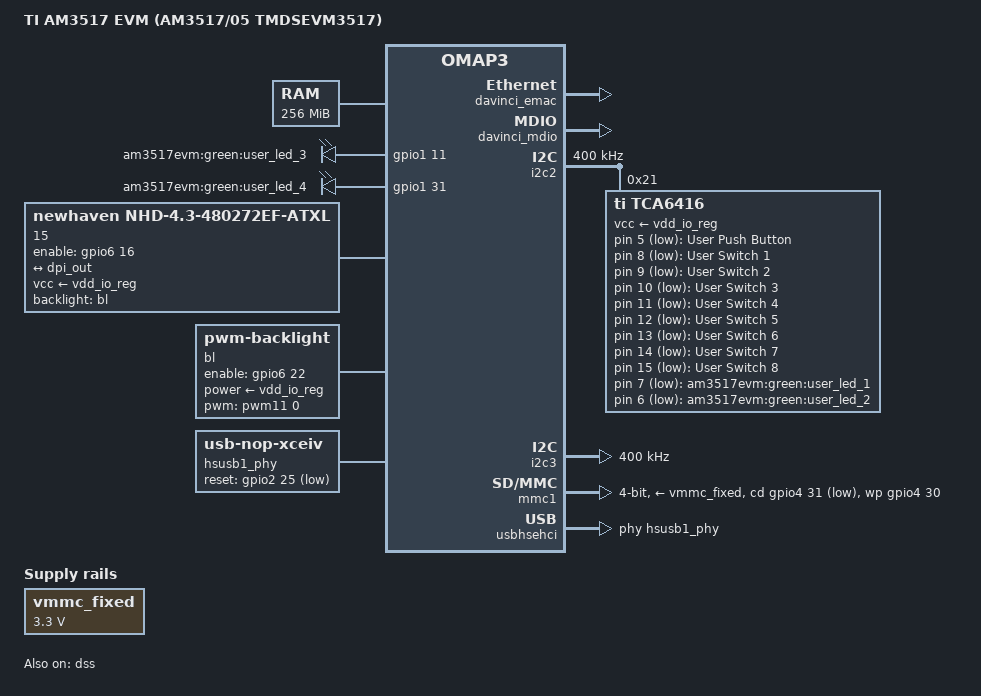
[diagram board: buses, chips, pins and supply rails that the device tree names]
/dts-v1/;
#include "am3517.dtsi"
#include "am3517-som.dtsi"
#include "am3517-evm-ui.dtsi"
#include <dt-bindings/input/input.h>
/ {
	model = "TI AM3517 EVM (AM3517/05 TMDSEVM3517)";
	compatible = "ti,am3517-evm", "ti,am3517", "ti,omap3";
	aliases {
		display0 = &lcd0;
	};
	chosen {
		stdout-path = &uart3;
	};
	memory@80000000 {
		device_type = "memory";
		reg = <0x80000000 0x10000000>;  
	};
	vmmc_fixed: vmmc {
		compatible = "regulator-fixed";
		regulator-name = "vmmc_fixed";
		regulator-min-microvolt = <3300000>;
		regulator-max-microvolt = <3300000>;
	};
	gpio-keys {
		compatible = "gpio-keys-polled";
		poll-interval = <100>;
		button-user {
			label = "User Push Button";
			linux,code = <BTN_0>;
			gpios = <&tca6416 5 GPIO_ACTIVE_LOW>;
		};
		switch-1 {
			label = "User Switch 1";
			linux,code = <BTN_1>;
			gpios = <&tca6416 8 GPIO_ACTIVE_LOW>;
		};
		switch-2 {
			label = "User Switch 2";
			linux,code = <BTN_2>;
			gpios = <&tca6416 9 GPIO_ACTIVE_LOW>;
		};
		switch-3 {
			label = "User Switch 3";
			linux,code = <BTN_3>;
			gpios = <&tca6416 10 GPIO_ACTIVE_LOW>;
		};
		switch-4 {
			label = "User Switch 4";
			linux,code = <BTN_4>;
			gpios = <&tca6416 11 GPIO_ACTIVE_LOW>;
		};
		switch-5 {
			label = "User Switch 5";
			linux,code = <BTN_5>;
			gpios = <&tca6416 12 GPIO_ACTIVE_LOW>;
		};
		switch-6 {
			label = "User Switch 6";
			linux,code = <BTN_6>;
			gpios = <&tca6416 13 GPIO_ACTIVE_LOW>;
		};
		switch-7 {
			label = "User Switch 7";
			linux,code = <BTN_7>;
			gpios = <&tca6416 14 GPIO_ACTIVE_LOW>;
		};
		switch-8 {
			label = "User Switch 8";
			linux,code = <BTN_8>;
			gpios = <&tca6416 15 GPIO_ACTIVE_LOW>;
		};
	};
	gpio-leds {
		compatible = "gpio-leds";
		pinctrl-names = "default";
		pinctrl-0 = <&leds_pins>;
		user_led_1 {
			label = "am3517evm:green:user_led_1";
			gpios = <&tca6416 7 GPIO_ACTIVE_LOW>;
			default-state = "on";
		};
		user_led_2 {
			label = "am3517evm:green:user_led_2";
			gpios = <&tca6416 6 GPIO_ACTIVE_LOW>;
			default-state = "on";
		};
		user_led_3 {
			label = "am3517evm:green:user_led_3";
			gpios = <&gpio1 11 GPIO_ACTIVE_HIGH>;
			linux,default-trigger = "mmc0";  
		};
		user_led_4 {
			label = "am3517evm:green:user_led_4";
			gpios = <&gpio1 31 GPIO_ACTIVE_HIGH>;
			linux,default-trigger = "heartbeat";
		};
	};
	lcd0: display@0 {
		compatible = "newhaven,nhd-4.3-480272ef-atxl";
		label = "15";
		backlight = <&bl>;
		enable-gpios = <&gpio6 16 GPIO_ACTIVE_HIGH>;	 
		vcc-supply = <&vdd_io_reg>;
		port {
			lcd_in: endpoint {
				remote-endpoint = <&dpi_out>;
			};
		};
	};
	bl: backlight {
		compatible = "pwm-backlight";
		pinctrl-names = "default";
		power-supply = <&vdd_io_reg>;
		pinctrl-0 = <&backlight_pins>;
		pwms = <&pwm11 0 5000000 0>;
		brightness-levels = <0 10 20 30 40 50 60 70 80 90 100>;
		default-brightness-level = <7>;
		enable-gpios = <&gpio6 22 GPIO_ACTIVE_HIGH>;  
	};
	pwm11: pwm-11 {
		compatible = "ti,omap-dmtimer-pwm";
		pinctrl-names = "default";
		pinctrl-0 = <&pwm_pins>;
		ti,timers = <&timer11>;
		#pwm-cells = <3>;
		ti,clock-source = <0x01>;
	};
	hsusb1_phy: hsusb1_phy {
		pinctrl-names = "default";
		pinctrl-0 = <&hsusb1_rst_pins>;
		compatible = "usb-nop-xceiv";
		reset-gpios = <&gpio2 25 GPIO_ACTIVE_LOW>;  
		#phy-cells = <0>;
	};
};
&davinci_emac {
	pinctrl-names = "default";
	pinctrl-0 = <&ethernet_pins>;
	status = "okay";
};
&davinci_mdio {
	status = "okay";
};
&dss {
	status = "okay";
	pinctrl-names = "default";
	pinctrl-0 = <&dss_dpi_pins>;
	vdds_dsi-supply = <&vdd_io_reg>;
	vdda_video-supply = <&vdd_io_reg>;
	port {
		dpi_out: endpoint {
			remote-endpoint = <&lcd_in>;
			data-lines = <16>;
		};
	};
};
&i2c2 {
	pinctrl-names = "default";
	pinctrl-0 = <&i2c2_pins>;
	clock-frequency = <400000>;
	tca6416: gpio@21 {
		compatible = "ti,tca6416";
		reg = <0x21>;
		gpio-controller;
		#gpio-cells = <2>;
		vcc-supply = <&vdd_io_reg>;
	};
};
&i2c3 {
	pinctrl-names = "default";
	pinctrl-0 = <&i2c3_pins>;
	clock-frequency = <400000>;
};
&mmc1 {
	status = "okay";
	pinctrl-names = "default";
	pinctrl-0 = <&mmc1_pins>;
	vmmc-supply = <&vmmc_fixed>;
	bus-width = <4>;
	wp-gpios = <&gpio4 30 GPIO_ACTIVE_HIGH>;  
	cd-gpios = <&gpio4 31 GPIO_ACTIVE_LOW>;  
};
&mmc3 {
	status = "disabled";
};
&usbhshost {
	pinctrl-names = "default";
	pinctrl-0 = <&hsusb1_pins>;
	port1-mode = "ehci-phy";
};
&usbhsehci {
	phys = <&hsusb1_phy>;
};
&omap3_pmx_core {
	ethernet_pins: ethernet-pins {
		pinctrl-single,pins = <
			OMAP3_CORE1_IOPAD(0x21fe, PIN_INPUT | MUX_MODE0)  
			OMAP3_CORE1_IOPAD(0x2200, MUX_MODE0)  
			OMAP3_CORE1_IOPAD(0x2202, PIN_INPUT_PULLDOWN | MUX_MODE0)  
			OMAP3_CORE1_IOPAD(0x2204, PIN_INPUT_PULLDOWN | MUX_MODE0)  
			OMAP3_CORE1_IOPAD(0x2206, PIN_INPUT_PULLDOWN | MUX_MODE0)  
			OMAP3_CORE1_IOPAD(0x2208, PIN_OUTPUT_PULLDOWN | MUX_MODE0)  
			OMAP3_CORE1_IOPAD(0x220a, PIN_OUTPUT_PULLDOWN | MUX_MODE0)  
			OMAP3_CORE1_IOPAD(0x220c, PIN_OUTPUT_PULLDOWN | MUX_MODE0)  
			OMAP3_CORE1_IOPAD(0x220e, PIN_OUTPUT_PULLDOWN |MUX_MODE0)  
			OMAP3_CORE1_IOPAD(0x2210, PIN_INPUT_PULLDOWN | MUX_MODE0)  
		>;
	};
	i2c2_pins: i2c2-pins {
		pinctrl-single,pins = <
			OMAP3_CORE1_IOPAD(0x21be, PIN_INPUT_PULLUP | MUX_MODE0)   
			OMAP3_CORE1_IOPAD(0x21c0, PIN_INPUT_PULLUP | MUX_MODE0)   
		>;
	};
	i2c3_pins: i2c3-pins {
		pinctrl-single,pins = <
			OMAP3_CORE1_IOPAD(0x21c2, PIN_INPUT_PULLUP | MUX_MODE0)   
			OMAP3_CORE1_IOPAD(0x21c4, PIN_INPUT_PULLUP | MUX_MODE0)   
		>;
	};
	mmc1_pins: mmc1-pins {
		pinctrl-single,pins = <
			OMAP3_CORE1_IOPAD(0x2144, PIN_INPUT_PULLUP | MUX_MODE0)	 
			OMAP3_CORE1_IOPAD(0x2146, PIN_INPUT_PULLUP | MUX_MODE0)	 
			OMAP3_CORE1_IOPAD(0x2148, PIN_INPUT_PULLUP | MUX_MODE0)	 
			OMAP3_CORE1_IOPAD(0x214a, PIN_INPUT_PULLUP | MUX_MODE0)	 
			OMAP3_CORE1_IOPAD(0x214c, PIN_INPUT_PULLUP | MUX_MODE0)	 
			OMAP3_CORE1_IOPAD(0x214e, PIN_INPUT_PULLUP | MUX_MODE0)	 
			OMAP3_CORE1_IOPAD(0x2150, PIN_INPUT_PULLUP | MUX_MODE4)  
			OMAP3_CORE1_IOPAD(0x2152, PIN_INPUT_PULLUP | MUX_MODE4)  
		>;
	};
	pwm_pins: pwm-pins {
		pinctrl-single,pins = <
			OMAP3_CORE1_IOPAD(0x21dc, PIN_OUTPUT | MUX_MODE1)        
		>;
	};
	backlight_pins: backlight-pins {
		pinctrl-single,pins = <
			OMAP3_CORE1_IOPAD(0x21de, PIN_OUTPUT | MUX_MODE4)        
		>;
	};
	dss_dpi_pins: dss-dpi-pins {
		pinctrl-single,pins = <
			OMAP3_CORE1_IOPAD(0x21d2, PIN_OUTPUT | MUX_MODE4)        
			OMAP3_CORE1_IOPAD(0x20d4, PIN_OUTPUT | MUX_MODE0)        
			OMAP3_CORE1_IOPAD(0x20d6, PIN_OUTPUT | MUX_MODE0)        
			OMAP3_CORE1_IOPAD(0x20d8, PIN_OUTPUT | MUX_MODE0)        
			OMAP3_CORE1_IOPAD(0x20da, PIN_OUTPUT | MUX_MODE0)        
			OMAP3_CORE1_IOPAD(0x20dc, PIN_OUTPUT | MUX_MODE0)        
			OMAP3_CORE1_IOPAD(0x20de, PIN_OUTPUT | MUX_MODE0)        
			OMAP3_CORE1_IOPAD(0x20e0, PIN_OUTPUT | MUX_MODE0)        
			OMAP3_CORE1_IOPAD(0x20e2, PIN_OUTPUT | MUX_MODE0)        
			OMAP3_CORE1_IOPAD(0x20e4, PIN_OUTPUT | MUX_MODE0)        
			OMAP3_CORE1_IOPAD(0x20e6, PIN_OUTPUT | MUX_MODE0)        
			OMAP3_CORE1_IOPAD(0x20e8, PIN_OUTPUT | MUX_MODE0)        
			OMAP3_CORE1_IOPAD(0x20ea, PIN_OUTPUT | MUX_MODE0)        
			OMAP3_CORE1_IOPAD(0x20ec, PIN_OUTPUT | MUX_MODE0)        
			OMAP3_CORE1_IOPAD(0x20ee, PIN_OUTPUT | MUX_MODE0)        
			OMAP3_CORE1_IOPAD(0x20f0, PIN_OUTPUT | MUX_MODE0)        
			OMAP3_CORE1_IOPAD(0x20f2, PIN_OUTPUT | MUX_MODE0)        
			OMAP3_CORE1_IOPAD(0x20f4, PIN_OUTPUT | MUX_MODE0)        
			OMAP3_CORE1_IOPAD(0x20f6, PIN_OUTPUT | MUX_MODE0)        
			OMAP3_CORE1_IOPAD(0x20f8, PIN_OUTPUT | MUX_MODE0)        
			OMAP3_CORE1_IOPAD(0x20fa, PIN_OUTPUT | MUX_MODE0)        
		>;
	};
	hsusb1_rst_pins: hsusb1-rst-pins {
		pinctrl-single,pins = <
			OMAP3_CORE1_IOPAD(0x20ba, PIN_OUTPUT | MUX_MODE4)	 
		>;
	};
};
&omap3_pmx_core2 {
	hsusb1_pins: hsusb1-pins {
		pinctrl-single,pins = <
			OMAP3430_CORE2_IOPAD(0x25d8, PIN_OUTPUT | MUX_MODE3)	 
			OMAP3430_CORE2_IOPAD(0x25da, PIN_OUTPUT | MUX_MODE3)	 
			OMAP3430_CORE2_IOPAD(0x25ec, PIN_INPUT | MUX_MODE3)	 
			OMAP3430_CORE2_IOPAD(0x25ee, PIN_INPUT | MUX_MODE3)	 
			OMAP3430_CORE2_IOPAD(0x25dc, PIN_INPUT | MUX_MODE3)	 
			OMAP3430_CORE2_IOPAD(0x25de, PIN_INPUT | MUX_MODE3)	 
			OMAP3430_CORE2_IOPAD(0x25e0, PIN_INPUT | MUX_MODE3)	 
			OMAP3430_CORE2_IOPAD(0x25ea, PIN_INPUT | MUX_MODE3)	 
			OMAP3430_CORE2_IOPAD(0x25e4, PIN_INPUT | MUX_MODE3)	 
			OMAP3430_CORE2_IOPAD(0x25e6, PIN_INPUT | MUX_MODE3)	 
			OMAP3430_CORE2_IOPAD(0x25e8, PIN_INPUT | MUX_MODE3)	 
			OMAP3430_CORE2_IOPAD(0x25e2, PIN_INPUT | MUX_MODE3)	 
		>;
	};
};
&omap3_pmx_wkup {
	leds_pins: leds-pins {
		pinctrl-single,pins = <
			OMAP3_WKUP_IOPAD(0x2a24, PIN_OUTPUT_PULLUP | MUX_MODE4)	 
			OMAP3_WKUP_IOPAD(0x2a26, PIN_OUTPUT_PULLUP | MUX_MODE4)	 
		>;
	};
};
